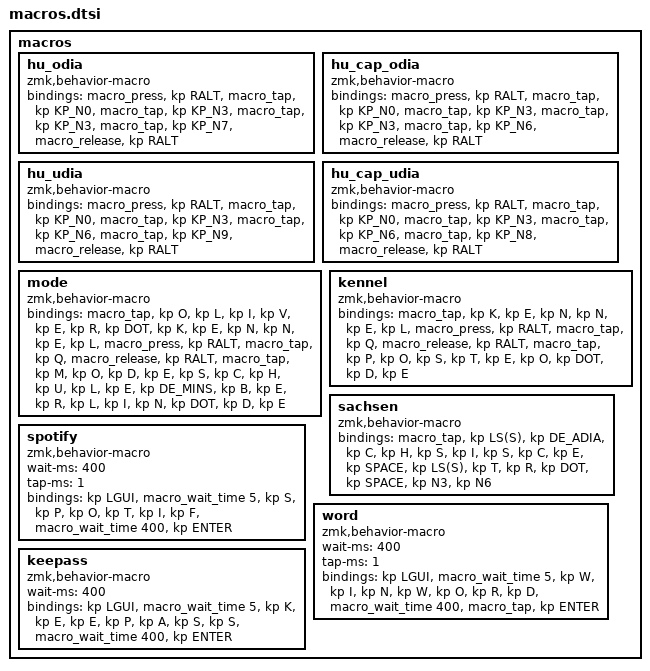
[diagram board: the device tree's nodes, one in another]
    macros {
/*/////////////// STEUERUNG ////////////////////////        
        selectline: selectline {
            compatible = "zmk,behavior-macro";
            #binding-cells = <0>;
            bindings
                = <&macro_tap &kp HOME>
                , <&macro_press &kp LSHFT>
                , <&macro_tap &kp END>
                , <&macro_release &kp LSHFT>
                ;
        };

        selectpara: selectpara {
            compatible = "zmk,behavior-macro";
            #binding-cells = <0>;
            bindings
                = <&macro_tap &kp LC(PG_UP)>
                , <&macro_press &kp LSHFT>
                , <&macro_tap &kp LC(PG_DN)>
                , <&macro_release &kp LSHFT>
                ;
        };

        new: new {
            compatible = "zmk,behavior-macro";
            #binding-cells = <0>;
            bindings
                = <&macro_tap &kp LC(N)>
                ;
        };

/////////////// SYMBOLE //////////////////////// 
        plus: plus {
            compatible = "zmk,behavior-macro";
            #binding-cells = <0>;
            bindings
                = <&macro_tap &kp PLUS>
                ;
        };   

        grad: grad {
            compatible = "zmk,behavior-macro";
            #binding-cells = <0>;
            bindings
                = <&macro_tap &kp B>
                , <&macro_tap &kp SPACE>
                , <&macro_tap &kp LS(C)>
                ;
        }; 



/////////////// UNGARISCH //////////////////////// 
        acc: acc {
            compatible = "zmk,behavior-macro-one-param";
            #binding-cells = <1>;
            bindings 
                = <&macro_tap &kp DE_ACUT>
                , <&macro_param_1to1>
                , <&kp MACRO_PLACEHOLDER>
            ;
        };
*/
        hu_odia: hu_odia {
            compatible = "zmk,behavior-macro";
            #binding-cells = <0>;
            bindings
                = <&macro_press &kp RALT>
                , <&macro_tap &kp KP_N0>
                , <&macro_tap &kp KP_N3>
                , <&macro_tap &kp KP_N3>
                , <&macro_tap &kp KP_N7>
                , <&macro_release &kp RALT>
                ;
        };

        hu_cap_odia: hu_cap_odia {
            compatible = "zmk,behavior-macro";
            #binding-cells = <0>;
            bindings
                = <&macro_press &kp RALT>
                , <&macro_tap &kp KP_N0>
                , <&macro_tap &kp KP_N3>
                , <&macro_tap &kp KP_N3>
                , <&macro_tap &kp KP_N6>
                , <&macro_release &kp RALT>
                ;
        };

        hu_udia: hu_udia {
            compatible = "zmk,behavior-macro";
            #binding-cells = <0>;
            bindings
                = <&macro_press &kp RALT>
                , <&macro_tap &kp KP_N0>
                , <&macro_tap &kp KP_N3>
                , <&macro_tap &kp KP_N6>
                , <&macro_tap &kp KP_N9>
                , <&macro_release &kp RALT>
                ;
        };

        hu_cap_udia: hu_cap_udia {
            compatible = "zmk,behavior-macro";
            #binding-cells = <0>;
            bindings
                = <&macro_press &kp RALT>
                , <&macro_tap &kp KP_N0>
                , <&macro_tap &kp KP_N3>
                , <&macro_tap &kp KP_N6>
                , <&macro_tap &kp KP_N8>
                , <&macro_release &kp RALT>
                ;
        }; 



/////////////// TEXT //////////////////////// 
        mode: mode { 
            compatible = "zmk,behavior-macro";
            #binding-cells = <0>;
            bindings
                = <&macro_tap &kp O &kp L &kp I &kp V &kp E &kp R &kp DOT &kp K &kp E &kp N &kp N &kp E &kp L>
                , <&macro_press &kp RALT>
                , <&macro_tap &kp Q>
                , <&macro_release &kp RALT>
                , <&macro_tap &kp M &kp O &kp D &kp E &kp S &kp C &kp H &kp U &kp L &kp E &kp DE_MINS &kp B &kp E &kp R &kp L &kp I &kp N &kp DOT &kp D &kp E>
                ;
        };

        kennel: kennel {
            compatible = "zmk,behavior-macro";
            #binding-cells = <0>;
            bindings
                = <&macro_tap &kp K &kp E &kp N &kp N &kp E &kp L>
                , <&macro_press &kp RALT>
                , <&macro_tap &kp Q>
                , <&macro_release &kp RALT>
                , <&macro_tap &kp P &kp O &kp S &kp T &kp E &kp O &kp DOT &kp D &kp E>
                ;
        }; 

        sachsen: sachsen {
            compatible = "zmk,behavior-macro";
            #binding-cells = <0>;
            bindings
                = <&macro_tap &kp LS(S) &kp DE_ADIA &kp C &kp H &kp S &kp I &kp S &kp C &kp E &kp SPACE &kp LS(S) &kp T &kp R &kp DOT &kp SPACE &kp N3 &kp N6>
                ;
        }; 


/////////////// APPS ÖFFNEN //////////////////////// 
        spotify: spotify {
            compatible = "zmk,behavior-macro";
            #binding-cells = <0>;
            wait-ms = <400>;
            tap-ms = <1>;
            bindings
                = <&kp LGUI>
                , <&macro_wait_time 5>
                , <&kp S &kp P &kp O &kp T &kp I &kp F>
                , <&macro_wait_time 400>
                , <&kp ENTER>
                ;
        };

        word: word {
            compatible = "zmk,behavior-macro";
            #binding-cells = <0>;
            wait-ms = <400>;
            tap-ms = <1>;
            bindings
                =  <&kp LGUI>
                , <&macro_wait_time 5>
                , <&kp W &kp I &kp N &kp W &kp O &kp R &kp D>
                , <&macro_wait_time 400>
                , <&macro_tap &kp ENTER>
                ;
        };

        keepass: keepass { 
            compatible = "zmk,behavior-macro";
            #binding-cells = <0>;
            wait-ms = <400>;
            bindings
                = <&kp LGUI>
                , <&macro_wait_time 5>
                , <&kp K &kp E &kp E &kp P &kp A &kp S &kp S>
                , <&macro_wait_time 400>
                , <&kp ENTER>
                ;
        };


    }; 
